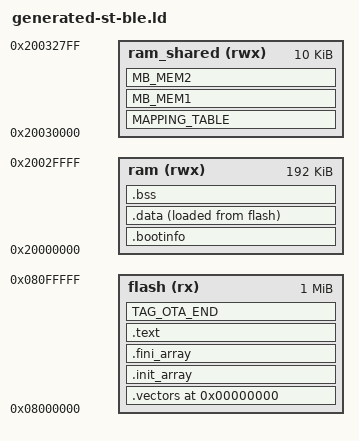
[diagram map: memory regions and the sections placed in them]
/*
 * This is the "normal" autogenerated laks linker script,
 * modified to include the "proper" sram2 mappings required
 * by the ST middle ware.
 */
MEMORY {
        flash (rx) : org = 0x8000000, len = 1M
        ram (rwx) : org = 0x20000000, len = 192k
        ram_shared (rwx) : org = 0x20030000, len = 10k
}

SECTIONS {
	. = 0;
	
	.vectors : ALIGN(16) SUBALIGN(16) {
		KEEP(*(.vectors))
	} > flash
	
	.init_array : ALIGN(4) SUBALIGN(4) {
		PROVIDE(_init_array_start = .);
		KEEP(*(SORT(.init_array.*)))
		KEEP(*(.init_array))
		PROVIDE(_init_array_end = .);
	} > flash
	
	.fini_array : ALIGN(4) SUBALIGN(4) {
		PROVIDE(_fini_array_start = .);
		KEEP(*(.fini_array))
		KEEP(*(SORT(.fini_array.*)))
		PROVIDE(_fini_array_end = .);
	} > flash
	
	.text : ALIGN(4) SUBALIGN(4) {
		*(.text.startup.*)
		*(.text)
		*(.text.*)
		*(.rodata)
		*(.rodata.*)
		*(.srodata)
		*(.srodata.*)
		*(.glue_7t)
		*(.glue_7)
		*(.gcc*)
	} > flash
	
	.bootinfo : ALIGN(4) SUBALIGN(4) {
		*(.bootinfo)
	} > ram
	
	. = ALIGN(4);
	
	.data : ALIGN(4) SUBALIGN(4) {
		PROVIDE(_data_start = .);
		*(.data)
		*(.data.*)
		*(.sdata)
		*(.sdata.*)
		*(.ramtext)
		PROVIDE(_data_end = .);
	} > ram AT > flash
	
	.bss : {
		PROVIDE(_bss_start = .);
		*(.bss)
		*(.bss.*)
		*(.sbss)
		*(.sbss.*)
		*(COMMON)
		PROVIDE(_bss_end = .);
	} > ram    
	
	PROVIDE(_ram_end = ORIGIN(ram) + LENGTH(ram));

	PROVIDE(_data_rom = LOADADDR(.data));

   MAPPING_TABLE (NOLOAD) : { *(MAPPING_TABLE) } >ram_shared
   MB_MEM1 (NOLOAD)       : { *(MB_MEM1) } >ram_shared
   MB_MEM2 (NOLOAD)       : { _sMB_MEM2 = . ; *(MB_MEM2) ; _eMB_MEM2 = . ; } >ram_shared
   TAG_OTA_END(NOLOAD)    : { KEEP (*(TAG_OTA_END)) } >flash   

}
